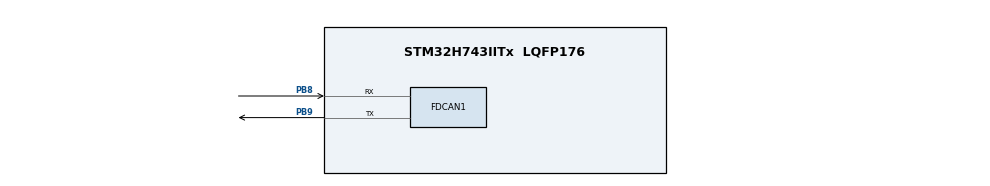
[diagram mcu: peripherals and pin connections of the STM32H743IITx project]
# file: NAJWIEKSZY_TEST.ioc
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FDCAN1.AutoRetransmission=ENABLE
FDCAN1.CalculateBaudRateNominal=500000
FDCAN1.CalculateTimeBitNominal=2000
FDCAN1.CalculateTimeQuantumNominal=80.0
FDCAN1.DataPrescaler=2
FDCAN1.DataSyncJumpWidth=12
FDCAN1.DataTimeSeg1=12
FDCAN1.DataTimeSeg2=7
FDCAN1.ExtFiltersNbr=5
FDCAN1.NominalPrescaler=2
FDCAN1.NominalSyncJumpWidth=7
FDCAN1.NominalTimeSeg1=17
FDCAN1.NominalTimeSeg2=7
FDCAN1.RxFifo0ElmtsNbr=1
FDCAN1.StdFiltersNbr=5
FDCAN1.TxFifoQueueElmtsNbr=3
Mcu.Family=STM32H7
Mcu.Name=STM32H743IITx
Mcu.Package=LQFP176
NVIC.FDCAN1_IT0_IRQn=true\:0\:0\:false\:false\:true\:true\:true\:true
NVIC.FDCAN1_IT1_IRQn=true\:0\:0\:false\:false\:true\:true\:true\:true
NVIC.FDCAN_CAL_IRQn=true\:0\:0\:false\:false\:true\:true\:true\:true
NVIC.PriorityGroup=NVIC_PRIORITYGROUP_4
PB8.Mode=FDCAN_Activate
PB8.Signal=FDCAN1_RX
PB9.GPIO_Speed=GPIO_SPEED_FREQ_VERY_HIGH
PB9.Mode=FDCAN_Activate
PB9.Signal=FDCAN1_TX
ProjectManager.HeapSize=0x200
ProjectManager.StackSize=0x400
ProjectManager.TargetToolchain=STM32CubeIDE
RCC.ADCFreq_Value=129000000
RCC.APB1Freq_Value=64000000
RCC.APB2Freq_Value=64000000
RCC.APB3Freq_Value=64000000
RCC.APB4Freq_Value=64000000
RCC.CortexFreq_Value=64000000
RCC.DIVM1=4
RCC.DIVN1=9
RCC.DIVQ1=6
RCC.HCLKFreq_Value=64000000
RCC.PLLFRACN=3072
RCC.SYSCLKFreq_VALUE=64000000
RCC.USBFreq_Value=25000000
VP_MEMORYMAP_VS_MEMORYMAP.Mode=CurAppReg
board=custom

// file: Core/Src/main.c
/* USER CODE BEGIN Header */
/**
  ******************************************************************************
  * @file           : main.c
  * @brief          : Main program body
  ******************************************************************************
  * @attention
  *
  * Copyright (c) 2025 STMicroelectronics.
  * All rights reserved.
  *
  * This software is licensed under terms that can be found in the LICENSE file
  * in the root directory of this software component.
  * If no LICENSE file comes with this software, it is provided AS-IS.
  *
  ******************************************************************************
  */
/* USER CODE END Header */
#include "main.h"

FDCAN_HandleTypeDef hfdcan1;

/* USER CODE BEGIN PV */
volatile float VESC_Voltage = 0.0f;
volatile float VESC_MosfetTemp = 0.0f;
volatile float VESC_MotorTemp = 0.0f;
/* USER CODE END PV */

void SystemClock_Config(void);
static void MX_GPIO_Init(void);
static void MX_FDCAN1_Init(void);

int main(void)
{

  /* MCU Configuration--------------------------------------------------------*/

  /* Reset of all peripherals, Initializes the Flash interface and the Systick. */
  HAL_Init();

  /* Configure the system clock */
  SystemClock_Config();

  /* Initialize all configured peripherals */
  MX_GPIO_Init();
  MX_FDCAN1_Init();
  /* USER CODE BEGIN 2 */
  // 1. Konfiguracja Filtra (Akceptuj wszystko - Extended ID)
    FDCAN_FilterTypeDef sFilterConfig;

    sFilterConfig.IdType = FDCAN_EXTENDED_ID;       // VESC używa 29-bit ID
    sFilterConfig.FilterIndex = 0;                  // Numer filtra (0)
    sFilterConfig.FilterType = FDCAN_FILTER_MASK;   // Tryb maski
    sFilterConfig.FilterConfig = FDCAN_FILTER_TO_RXFIFO0; // Przekaż do FIFO0

    // Ustawienie ID i Maski na 0 oznacza "bierz wszystko"
    sFilterConfig.FilterID1 = 0x00000000;
    sFilterConfig.FilterID2 = 0x00000000;

    if (HAL_FDCAN_ConfigFilter(&hfdcan1, &sFilterConfig) != HAL_OK)
    {
      Error_Handler();
    }

    // 2. Konfiguracja Globalnego Filtra (Ważne w FDCAN!)
    // Jeśli filtr powyżej nie zadziała, to ustawienie pozwoli odrzucić śmieci,
    // ale zaakceptować ramki pasujące do filtra.
    // Często domyślnie FDCAN odrzuca wszystko, co nie pasuje (Reject).
    if (HAL_FDCAN_ConfigGlobalFilter(&hfdcan1,
                                     FDCAN_ACCEPT_IN_RX_FIFO0, // Std ID -> Akceptuj
                                     FDCAN_ACCEPT_IN_RX_FIFO0, // Ext ID -> Akceptuj <--- TU BYŁ PROBLEM
                                     FDCAN_FILTER_REMOTE,
                                     FDCAN_FILTER_REMOTE) != HAL_OK)
    {
        Error_Handler();
    }

    // 3. Start modułu FDCAN
    if (HAL_FDCAN_Start(&hfdcan1) != HAL_OK)
    {
      Error_Handler();
    }

    // 4. Aktywacja przerwania (RX FIFO 0 New Message)
    // Zwróć uwagę na inną nazwę flagi niż w starym CAN!
    if (HAL_FDCAN_ActivateNotification(&hfdcan1, FDCAN_IT_RX_FIFO0_NEW_MESSAGE, 0) != HAL_OK)
    {
      Error_Handler();
    }
  /* USER CODE END 2 */

  /* Infinite loop */
  while (1)
  {

  }
}

void SystemClock_Config(void)
{
  RCC_OscInitTypeDef RCC_OscInitStruct = {0};
  RCC_ClkInitTypeDef RCC_ClkInitStruct = {0};

  /** Supply configuration update enable
  */
  HAL_PWREx_ConfigSupply(PWR_LDO_SUPPLY);

  /** Configure the main internal regulator output voltage
  */
  __HAL_PWR_VOLTAGESCALING_CONFIG(PWR_REGULATOR_VOLTAGE_SCALE3);

  while(!__HAL_PWR_GET_FLAG(PWR_FLAG_VOSRDY)) {}

  /** Initializes the RCC Oscillators according to the specified parameters
  * in the RCC_OscInitTypeDef structure.
  */
  RCC_OscInitStruct.OscillatorType = RCC_OSCILLATORTYPE_HSI;
  RCC_OscInitStruct.HSIState = RCC_HSI_DIV1;
  RCC_OscInitStruct.HSICalibrationValue = RCC_HSICALIBRATION_DEFAULT;
  RCC_OscInitStruct.PLL.PLLState = RCC_PLL_ON;
  RCC_OscInitStruct.PLL.PLLSource = RCC_PLLSOURCE_HSI;
  RCC_OscInitStruct.PLL.PLLM = 4;
  RCC_OscInitStruct.PLL.PLLN = 9;
  RCC_OscInitStruct.PLL.PLLP = 2;
  RCC_OscInitStruct.PLL.PLLQ = 6;
  RCC_OscInitStruct.PLL.PLLR = 2;
  RCC_OscInitStruct.PLL.PLLRGE = RCC_PLL1VCIRANGE_3;
  RCC_OscInitStruct.PLL.PLLVCOSEL = RCC_PLL1VCOMEDIUM;
  RCC_OscInitStruct.PLL.PLLFRACN = 3072;
  if (HAL_RCC_OscConfig(&RCC_OscInitStruct) != HAL_OK)
  {
    Error_Handler();
  }

  /** Initializes the CPU, AHB and APB buses clocks
  */
  RCC_ClkInitStruct.ClockType = RCC_CLOCKTYPE_HCLK|RCC_CLOCKTYPE_SYSCLK
                              |RCC_CLOCKTYPE_PCLK1|RCC_CLOCKTYPE_PCLK2
                              |RCC_CLOCKTYPE_D3PCLK1|RCC_CLOCKTYPE_D1PCLK1;
  RCC_ClkInitStruct.SYSCLKSource = RCC_SYSCLKSOURCE_HSI;
  RCC_ClkInitStruct.SYSCLKDivider = RCC_SYSCLK_DIV1;
  RCC_ClkInitStruct.AHBCLKDivider = RCC_HCLK_DIV1;
  RCC_ClkInitStruct.APB3CLKDivider = RCC_APB3_DIV1;
  RCC_ClkInitStruct.APB1CLKDivider = RCC_APB1_DIV1;
  RCC_ClkInitStruct.APB2CLKDivider = RCC_APB2_DIV1;
  RCC_ClkInitStruct.APB4CLKDivider = RCC_APB4_DIV1;

  if (HAL_RCC_ClockConfig(&RCC_ClkInitStruct, FLASH_LATENCY_1) != HAL_OK)
  {
    Error_Handler();
  }
}

static void MX_FDCAN1_Init(void)
{

  hfdcan1.Instance = FDCAN1;
  hfdcan1.Init.FrameFormat = FDCAN_FRAME_CLASSIC;
  hfdcan1.Init.Mode = FDCAN_MODE_NORMAL;
  hfdcan1.Init.AutoRetransmission = ENABLE;
  hfdcan1.Init.TransmitPause = DISABLE;
  hfdcan1.Init.ProtocolException = DISABLE;
  hfdcan1.Init.NominalPrescaler = 2;
  hfdcan1.Init.NominalSyncJumpWidth = 7;
  hfdcan1.Init.NominalTimeSeg1 = 17;
  hfdcan1.Init.NominalTimeSeg2 = 7;
  hfdcan1.Init.DataPrescaler = 2;
  hfdcan1.Init.DataSyncJumpWidth = 12;
  hfdcan1.Init.DataTimeSeg1 = 12;
  hfdcan1.Init.DataTimeSeg2 = 7;
  hfdcan1.Init.MessageRAMOffset = 0;
  hfdcan1.Init.StdFiltersNbr = 5;
  hfdcan1.Init.ExtFiltersNbr = 5;
  hfdcan1.Init.RxFifo0ElmtsNbr = 1;
  hfdcan1.Init.RxFifo0ElmtSize = FDCAN_DATA_BYTES_8;
  hfdcan1.Init.RxFifo1ElmtsNbr = 0;
  hfdcan1.Init.RxFifo1ElmtSize = FDCAN_DATA_BYTES_8;
  hfdcan1.Init.RxBuffersNbr = 0;
  hfdcan1.Init.RxBufferSize = FDCAN_DATA_BYTES_8;
  hfdcan1.Init.TxEventsNbr = 0;
  hfdcan1.Init.TxBuffersNbr = 0;
  hfdcan1.Init.TxFifoQueueElmtsNbr = 3;
  hfdcan1.Init.TxFifoQueueMode = FDCAN_TX_FIFO_OPERATION;
  hfdcan1.Init.TxElmtSize = FDCAN_DATA_BYTES_8;
  if (HAL_FDCAN_Init(&hfdcan1) != HAL_OK)
  {
    Error_Handler();
  }

}

static void MX_GPIO_Init(void)
{

  /* GPIO Ports Clock Enable */
  __HAL_RCC_GPIOB_CLK_ENABLE();

}

/* USER CODE BEGIN 4 */
void HAL_FDCAN_RxFifo0Callback(FDCAN_HandleTypeDef *hfdcan, uint32_t RxFifo0ITs)
{
    // Sprawdź, czy przerwanie pochodzi z FIFO 0 od nowej wiadomości
    if((RxFifo0ITs & FDCAN_IT_RX_FIFO0_NEW_MESSAGE) != 0)
    {
        FDCAN_RxHeaderTypeDef rxHeader;
        uint8_t rxData[8];

        // Pobierz wiadomość
        if (HAL_FDCAN_GetRxMessage(hfdcan, FDCAN_RX_FIFO0, &rxHeader, rxData) == HAL_OK)
        {
            // W FDCAN ID znajduje się zawsze w polu "Identifier"

            // --- STATUS 4 (0x104A dla ID 74) -> Temperatury ---
            if (rxHeader.Identifier == 0x0000104A)
            {
                int16_t temp_fet_raw = (int16_t)((rxData[0] << 8) | rxData[1]);
                VESC_MosfetTemp = (float)temp_fet_raw / 10.0f;

                int16_t temp_motor_raw = (int16_t)((rxData[2] << 8) | rxData[3]);
                VESC_MotorTemp = (float)temp_motor_raw / 10.0f;
            }

            // --- STATUS 5 (0x1B4A dla ID 74) -> Napięcie ---
            else if (rxHeader.Identifier == 0x00001B4A)
            {
                int16_t voltage_raw = (int16_t)((rxData[4] << 8) | rxData[5]);
                VESC_Voltage = (float)voltage_raw / 10.0f;
            }
        }
    }
}

void Try_Send_Duty(void)
{
    FDCAN_TxHeaderTypeDef TxHeader;
    uint8_t TxData[4];

    // VESC ID = 74 (0x4A). Komenda Duty = 0.
    // Pełne ID = 0x0000004A
    TxHeader.Identifier = 0x0000004A;
    TxHeader.IdType = FDCAN_EXTENDED_ID;      // VESC WYMAGA EXTENDED!
    TxHeader.TxFrameType = FDCAN_DATA_FRAME;
    TxHeader.DataLength = FDCAN_DLC_BYTES_4;  // 4 bajty danych
    TxHeader.ErrorStateIndicator = FDCAN_ESI_ACTIVE;
    TxHeader.BitRateSwitch = FDCAN_BRS_OFF;   // WAŻNE: Wyłączone
    TxHeader.FDFormat = FDCAN_CLASSIC_CAN;    // WAŻNE: Classic
    TxHeader.TxEventFifoControl = FDCAN_NO_TX_EVENTS;
    TxHeader.MessageMarker = 0;

    // Dane: Duty 10% (0.10 * 100000 = 10000)
    // 10000 decimal = 0x00002710 hex
    // Big Endian:
    TxData[0] = 0x00;
    TxData[1] = 0x00;
    TxData[2] = 0x27;
    TxData[3] = 0x10;

    // Próba wysłania
    if (HAL_FDCAN_AddMessageToTxFifoQ(&hfdcan1, &TxHeader, TxData) != HAL_OK)
    {
        // Jeśli tu wpada -> Kolejka pełna -> Poprzednie wiadomości nie wyszły
        // Opcjonalnie: Wyczyść kolejkę "na siłę" żeby spróbować z nową
        HAL_FDCAN_AbortTxRequest(&hfdcan1, FDCAN_TX_BUFFER0 | FDCAN_TX_BUFFER1 | FDCAN_TX_BUFFER2);
    }
}
/* USER CODE END 4 */

void Error_Handler(void)
{
  __disable_irq();
  while (1)
  {
  }
}
